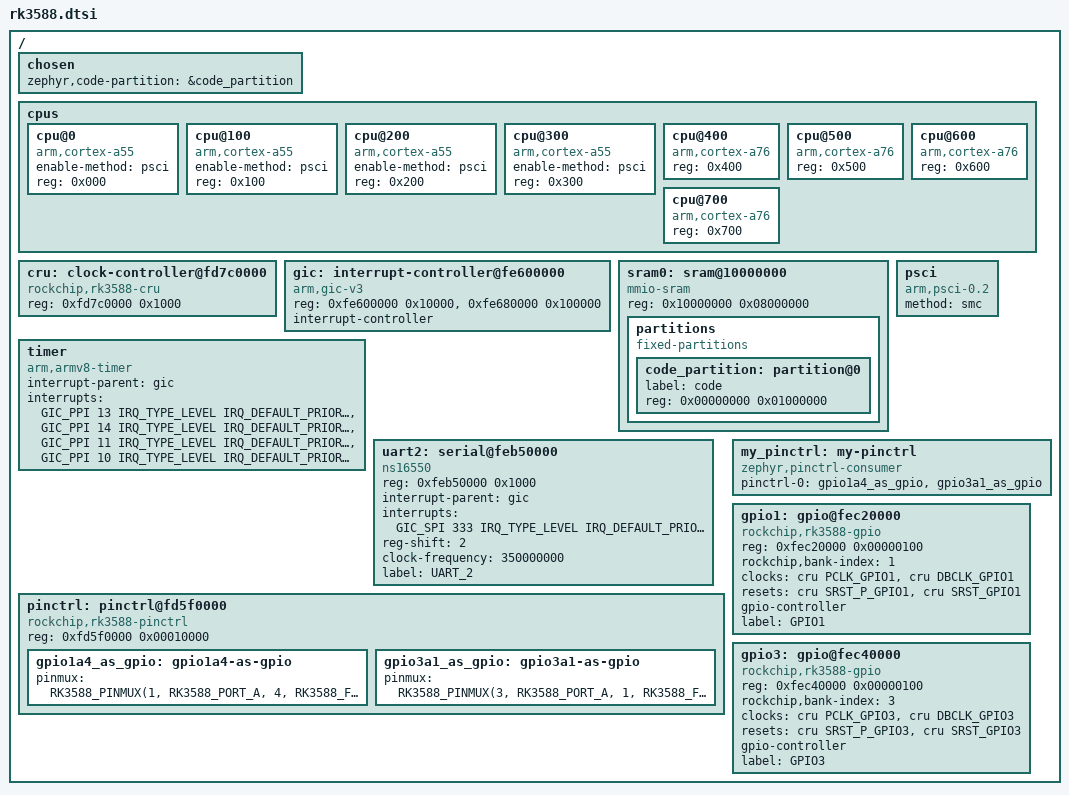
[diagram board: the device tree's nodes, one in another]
/*
 * Copyright 2024 Université Gustave Eiffel
 * SPDX-License-Identifier: Apache-2.0
 */

#include <arm64/armv8-a.dtsi>
#include <zephyr/dt-bindings/interrupt-controller/arm-gic.h>
#include <zephyr/dt-bindings/pinctrl/rockchip-rk3588-pinctrl.h>
#include <dt-bindings/clock/rk3588-cru.h>

#include <mem.h>

 / {
	#address-cells = <1>;
	#size-cells = <1>;

	chosen {
		zephyr,code-partition = &code_partition;
	};

	cpus {
		#address-cells = <1>;
		#size-cells = <0>;

		cpu@0 {
			device_type = "cpu";
			compatible = "arm,cortex-a55";
			enable-method = "psci";
			reg = <0x000>;
		};

		cpu@100 {
			device_type = "cpu";
			compatible = "arm,cortex-a55";
			enable-method = "psci";
			reg = <0x100>;
		};

		cpu@200 {
			device_type = "cpu";
			compatible = "arm,cortex-a55";
			enable-method = "psci";
			reg = <0x200>;
		};

		cpu@300 {
			device_type = "cpu";
			compatible = "arm,cortex-a55";
			enable-method = "psci";
			reg = <0x300>;
		};

		cpu@400 {
			device_type = "cpu";
			compatible = "arm,cortex-a76";
			reg = <0x400>;
		};

		cpu@500 {
			device_type = "cpu";
			compatible = "arm,cortex-a76";
			reg = <0x500>;
		};

		cpu@600 {
			device_type = "cpu";
			compatible = "arm,cortex-a76";
			reg = <0x600>;
		};

		cpu@700 {
			device_type = "cpu";
			compatible = "arm,cortex-a76";
			reg = <0x700>;
		};
	};

	cru: clock-controller@fd7c0000 {
		compatible = "rockchip,rk3588-cru";
		reg = <0xfd7c0000 0x1000>;
		#clock-cells = <1>;
		#reset-cells = <1>;
	};

	gic: interrupt-controller@fe600000  {
		#address-cells = <1>;
		compatible = "arm,gic-v3", "arm,gic";
		reg = <0xfe600000 0x10000>, /* GICD */
		      <0xfe680000 0x100000>; /* GICR */
		interrupt-controller;
		#interrupt-cells = <4>;
		status = "okay";
	};

	sram0: sram@10000000 {
        compatible = "mmio-sram";
        reg = <0x10000000 0x08000000>; /* 128 MiB */
        /* Nel bus SRAM usiamo offset e size a 32 bit (1 cell) */
        #address-cells = <1>;
        #size-cells = <1>;
        /* ranges: child-addr(1)  parent-addr(2)      size(1) */
        ranges = <0x0 0x10000000 0x08000000>;

        partitions: partitions {
            compatible = "fixed-partitions";
            #address-cells = <1>;
            #size-cells = <1>;

            /* Code RX all'inizio: offset 0 (== 0x10000000 fisico), 16 MiB */
            code_partition: partition@0 {
                label = "code";
                reg = <0x00000000  0x01000000>;  /* 16 MiB */
            };
        };
    };

	psci {
		compatible = "arm,psci-0.2", "arm,psci";
		method = "smc";
	};

	timer {
		compatible = "arm,armv8-timer";
		interrupt-parent = <&gic>;
		interrupts = <GIC_PPI 13 IRQ_TYPE_LEVEL
			      IRQ_DEFAULT_PRIORITY>,
			     <GIC_PPI 14 IRQ_TYPE_LEVEL
			      IRQ_DEFAULT_PRIORITY>,
			     <GIC_PPI 11 IRQ_TYPE_LEVEL
			      IRQ_DEFAULT_PRIORITY>,
			     <GIC_PPI 10 IRQ_TYPE_LEVEL
			      IRQ_DEFAULT_PRIORITY>;
	};


	
	uart2: serial@feb50000  {
		compatible = "ns16550";
		reg = <0xfeb50000 0x1000>;
		interrupt-parent = <&gic>;
		interrupts = <GIC_SPI 333 IRQ_TYPE_LEVEL IRQ_DEFAULT_PRIORITY>;
		status = "okay";
		reg-shift = <2>;
		clock-frequency = <350000000>;
		label = "UART_2";
	};

	/* Pinctrl BUS_IOC controller */
	pinctrl: pinctrl@fd5f0000 {
		compatible = "rockchip,rk3588-pinctrl";
		reg = <0xfd5f0000 0x00010000>; /* BUS_IOC */
		status = "okay";

		/* Stati per pin del 40-pin header: pin 11 = GPIO1_A4, pin 12 = GPIO3_A1 */
		gpio1a4_as_gpio: gpio1a4-as-gpio {
			/* bank=1, port=A(0), pin=4, func=GPIO(0) */
			pinmux = <RK3588_PINMUX(1, RK3588_PORT_A, 4, RK3588_FUNC_GPIO)>;
		};

		gpio3a1_as_gpio: gpio3a1-as-gpio {
			/* bank=3, port=A(0), pin=1, func=GPIO(0) */
			pinmux = <RK3588_PINMUX(3, RK3588_PORT_A, 1, RK3588_FUNC_GPIO)>;
		};
	};

	/* Helper consumer per applicare lo state via pinctrl_apply_state() */
	my_pinctrl: my-pinctrl {
		compatible = "zephyr,pinctrl-consumer";
		pinctrl-0 = <&gpio1a4_as_gpio &gpio3a1_as_gpio>;
		pinctrl-names = "default";
		status = "okay";
	};

	/* GPIO1 controller (for header pin 11 = GPIO1_A4) */
	gpio1: gpio@fec20000 {
		compatible = "rockchip,rk3588-gpio";
		reg = <0xfec20000 0x00000100>;
		rockchip,bank-index = <1>;
		clocks = <&cru PCLK_GPIO1>, <&cru DBCLK_GPIO1>;
		clock-names = "pclk", "dbclk";
		resets = <&cru SRST_P_GPIO1>, <&cru SRST_GPIO1>;
		reset-names = "pclk", "core";
		gpio-controller;
		#gpio-cells = <2>;
		label = "GPIO1";
		status = "okay";
	};

	/* GPIO3 controller (for header pin 12 = GPIO3_A1) */
	gpio3: gpio@fec40000 {
		compatible = "rockchip,rk3588-gpio";
		reg = <0xfec40000 0x00000100>;
		rockchip,bank-index = <3>;
		clocks = <&cru PCLK_GPIO3>, <&cru DBCLK_GPIO3>;
		clock-names = "pclk", "dbclk";
		resets = <&cru SRST_P_GPIO3>, <&cru SRST_GPIO3>;
		reset-names = "pclk", "core";
		gpio-controller;
		#gpio-cells = <2>;
		label = "GPIO3";
		status = "okay";
	};

	

};
